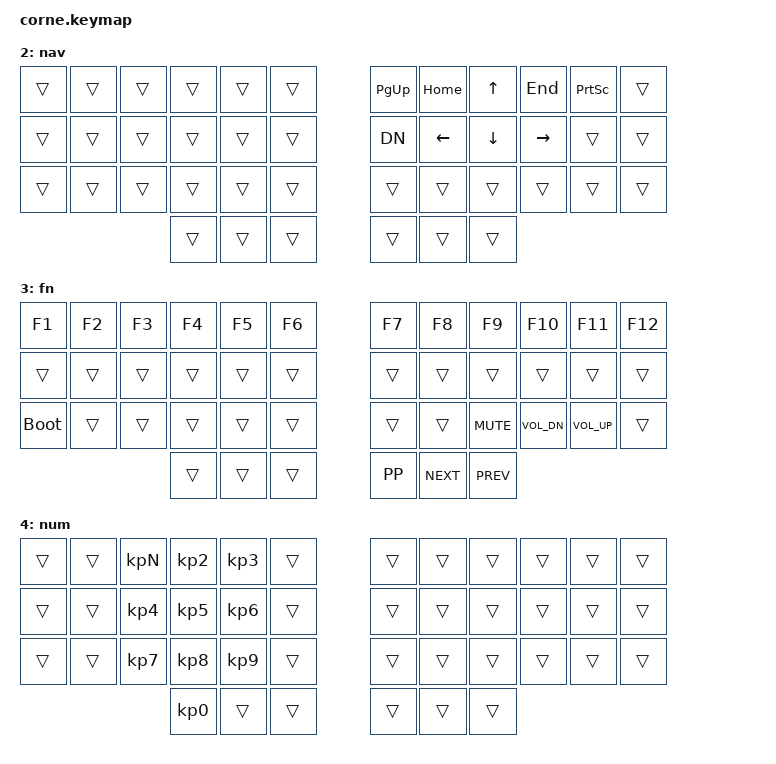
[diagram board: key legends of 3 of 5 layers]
/*
 * Copyright (c) 2020 The ZMK Contributors
 *
 * SPDX-License-Identifier: MIT
 */

#include <behaviors.dtsi>
#include <dt-bindings/zmk/keys.h>
#include <dt-bindings/zmk/bt.h>
#include "keys_de.h"

/ {
        keymap {
                compatible = "zmk,keymap";

                char_layer {
                        display-name = "char";
                        bindings = <
   &kp ESC        &kp Q    &kp W       &kp E      &kp R      &kp T           &kp DE_Z    &kp U       &kp I        &kp O       &kp P           &kp DE_U_UMLAUT
   &kp TAB        &kp A    &mt LCTRL S &mt LALT D &mt LGUI F &kp G           &kp H       &mt RGUI J  &mt RALT K   &mt RCTRL L &kp DE_O_UMLAUT &kp DE_A_UMLAUT
   &kp &caps_word &kp DE_Y &kp X       &kp C      &kp V      &kp B           &kp N       &kp M       &kp DE_COMMA &kp DE_DOT  &kp DE_MINUS    &mo 3
                                       &kp DEL    &mo 4      &kp LSHIFT      &lt 1 RET   &lt 2 SPACE &kp BSPC
                        >;
                };
                sym_layer {
                        display-name = "sym";
                        bindings = <
   &trans     &kp DE_EXCL  &kp DE_EURO       &kp DE_LBRC      &kp DE_RBRC      &kp DE_PIPE      &trans     &kp DE_PLUS       &kp DE_DQT      &kp DE_ASTRK       &kp DE_POUND &kp DE_SZ
   &kp DE_DEG &kp DE_CARET &mt LCTRL DE_DLLR &mt LALT DE_LPAR &mt LGUI DE_RPAR &kp DE_FSLH      &kp DE_AT  &mt RGUI DE_TILDE &mt RALT DE_SQT &mt RCTRL DE_EQUAL &kp DE_QMARK &kp DE_SECT
   &trans     &kp DE_PRCNT &kp DE_AMPS       &kp DE_LBKT      &kp DE_RBKT      &kp DE_BSLH      &trans     &trans            &kp DE_ACUTE    &kp DE_GRAVE       &trans       &trans
                                             &kp DE_LT        &kp DE_GT        &trans           &kp &none  &trans            &trans
                        >;
                };
                nav_layer {
                        display-name = "nav";
                        bindings = <
   &trans &trans &trans &trans &trans &trans      &kp PG_UP &kp HOME  &kp UP   &kp END   &kp PSCRN &trans
   &trans &trans &trans &trans &trans &trans      &kp DN    &kp LEFT  &kp DOWN &kp RIGHT &trans    &trans
   &trans &trans &trans &trans &trans &trans      &trans    &trans    &trans   &trans    &trans    &trans
                        &trans &trans &trans      &trans    &trans    &trans
                        >;
                };
                fn_layer {
                        display-name = "fn";
                        bindings = <
   &kp F1      &kp F2 &kp F3 &kp F4 &kp F5 &kp F6      &kp F7   &kp F8     &kp F9     &kp F10      &kp F11      &kp F12
   &trans      &trans &trans &trans &trans &trans      &trans   &trans     &trans     &trans       &trans       &trans
   &bootloader &trans &trans &trans &trans &trans      &trans   &trans     &kp K_MUTE &kp K_VOL_DN &kp K_VOL_UP &trans
                             &trans &trans &trans      &kp K_PP &kp K_NEXT &kp K_PREV
                        >;
                };
                num_layer {
                        display-name = "num";
                        bindings = <
   &trans &trans &kp KP_N  &kp KP_N2 &kp KP_N3 &trans      &trans &trans &trans &trans &trans &trans
   &trans &trans &kp KP_N4 &kp KP_N5 &kp KP_N6 &trans      &trans &trans &trans &trans &trans &trans
   &trans &trans &kp KP_N7 &kp KP_N8 &kp KP_N9 &trans      &trans &trans &trans &trans &trans &trans
                           &kp KP_N0 &trans    &trans      &trans &trans &trans
                        >;
                };
//                trans_layer {
//                        display-name = "trans";
//                        bindings = <
//   &trans &trans &trans &trans &trans &trans      &trans &trans &trans &trans &trans &trans
//   &trans &trans &trans &trans &trans &trans      &trans &trans &trans &trans &trans &trans
//   &trans &trans &trans &trans &trans &trans      &trans &trans &trans &trans &trans &trans
//                        &trans &trans &trans      &trans &trans &trans
//                        >;
//                };
        };
};
